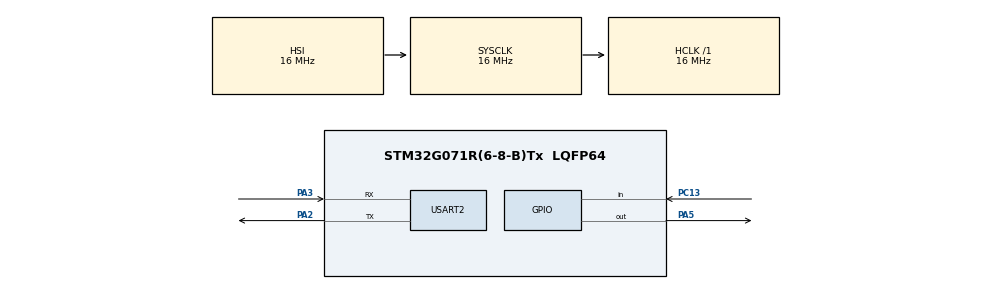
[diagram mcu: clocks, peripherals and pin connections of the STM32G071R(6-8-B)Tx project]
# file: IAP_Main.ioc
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CRC.CRCLength=CRC_POLYLENGTH_16B
CRC.DefaultInitValueUse=DEFAULT_INIT_VALUE_DISABLE
CRC.DefaultPolynomialUse=DEFAULT_POLYNOMIAL_DISABLE
Mcu.Family=STM32G0
Mcu.Name=STM32G071R(6-8-B)Tx
Mcu.Package=LQFP64
PA2.Mode=Asynchronous
PA2.Signal=USART2_TX
PA3.Mode=Asynchronous
PA3.Signal=USART2_RX
PA5.Signal=GPIO_Output
PC13.Signal=GPIO_Input
ProjectManager.HeapSize=0x200
ProjectManager.StackSize=0x400
ProjectManager.TargetToolchain=STM32CubeIDE
RCC.AHBFreq_Value=16000000
RCC.CortexFreq_Value=16000000
RCC.EXTERNAL_CLOCK_VALUE=12288000
RCC.HCLKFreq_Value=16000000
RCC.HSE_VALUE=8000000
RCC.HSI_VALUE=16000000
RCC.LSE_VALUE=32768
RCC.SYSCLKFreq_VALUE=16000000
RCC.VCOOutputFreq_Value=128000000
USART2.VirtualMode-Asynchronous=VM_ASYNC
VP_CRC_VS_CRC.Mode=CRC_Activate
board=NUCLEO-G071RB

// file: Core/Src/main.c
/* USER CODE BEGIN Header */
/**
  ******************************************************************************
  * @file           : main.c
  * @brief          : Main program body
  ******************************************************************************
  * @attention
  *
  * Copyright (c) 2023 STMicroelectronics.
  * All rights reserved.
  *
  * This software is licensed under terms that can be found in the LICENSE file
  * in the root directory of this software component.
  * If no LICENSE file comes with this software, it is provided AS-IS.
  *
  ******************************************************************************
  */
/* USER CODE END Header */
#include "main.h"

/* USER CODE BEGIN Includes */
#include "menu.h"
/* USER CODE END Includes */

CRC_HandleTypeDef hcrc;

UART_HandleTypeDef huart2;

/* USER CODE BEGIN PV */
extern pFunction JumpToApplication;
extern uint32_t JumpAddress;
/* USER CODE END PV */

void SystemClock_Config(void);
static void MX_GPIO_Init(void);
static void MX_USART2_UART_Init(void);
static void MX_CRC_Init(void);

int main(void)
{

  /* MCU Configuration--------------------------------------------------------*/

  /* Reset of all peripherals, Initializes the Flash interface and the Systick. */
  HAL_Init();

  /* Configure the system clock */
  SystemClock_Config();

  /* Initialize all configured peripherals */
  MX_GPIO_Init();
  MX_USART2_UART_Init();
  MX_CRC_Init();
  /* USER CODE BEGIN 2 */
  if (HAL_GPIO_ReadPin(BTN1_GPIO_Port,BTN1_Pin) == GPIO_PIN_SET)
  {
	  /* Initialise Flash */
	  FLASH_If_Init();
	  /* Display main menu */
	  Main_Menu ();
  }
  /* Keep the user application running */
  else
  {
	  /* Test if user code is programmed starting from address "APPLICATION_ADDRESS" */
	  if (((*(__IO uint32_t*)APPLICATION_ADDRESS) & 0x2FFE0000 ) == 0x20000000)
	  {
		  /* Jump to user application */
		  JumpAddress = *(__IO uint32_t*) (APPLICATION_ADDRESS + 4);
		  JumpToApplication = (pFunction) JumpAddress;
		  /* Initialize user application's Stack Pointer */
		  __set_MSP(*(__IO uint32_t*) APPLICATION_ADDRESS);
		  JumpToApplication();
	  }
  }
  /* USER CODE END 2 */

  /* Infinite loop */
  while (1)
  {

  }
}

void SystemClock_Config(void)
{
  RCC_OscInitTypeDef RCC_OscInitStruct = {0};
  RCC_ClkInitTypeDef RCC_ClkInitStruct = {0};

  /** Configure the main internal regulator output voltage
  */
  HAL_PWREx_ControlVoltageScaling(PWR_REGULATOR_VOLTAGE_SCALE1);

  /** Initializes the RCC Oscillators according to the specified parameters
  * in the RCC_OscInitTypeDef structure.
  */
  RCC_OscInitStruct.OscillatorType = RCC_OSCILLATORTYPE_HSI;
  RCC_OscInitStruct.HSIState = RCC_HSI_ON;
  RCC_OscInitStruct.HSIDiv = RCC_HSI_DIV1;
  RCC_OscInitStruct.HSICalibrationValue = RCC_HSICALIBRATION_DEFAULT;
  RCC_OscInitStruct.PLL.PLLState = RCC_PLL_NONE;
  if (HAL_RCC_OscConfig(&RCC_OscInitStruct) != HAL_OK)
  {
    Error_Handler();
  }

  /** Initializes the CPU, AHB and APB buses clocks
  */
  RCC_ClkInitStruct.ClockType = RCC_CLOCKTYPE_HCLK|RCC_CLOCKTYPE_SYSCLK
                              |RCC_CLOCKTYPE_PCLK1;
  RCC_ClkInitStruct.SYSCLKSource = RCC_SYSCLKSOURCE_HSI;
  RCC_ClkInitStruct.AHBCLKDivider = RCC_SYSCLK_DIV1;
  RCC_ClkInitStruct.APB1CLKDivider = RCC_HCLK_DIV1;

  if (HAL_RCC_ClockConfig(&RCC_ClkInitStruct, FLASH_LATENCY_0) != HAL_OK)
  {
    Error_Handler();
  }
}

static void MX_CRC_Init(void)
{

  hcrc.Instance = CRC;
  hcrc.Init.DefaultPolynomialUse = DEFAULT_POLYNOMIAL_DISABLE;
  hcrc.Init.DefaultInitValueUse = DEFAULT_INIT_VALUE_DISABLE;
  hcrc.Init.GeneratingPolynomial = 0x1021;  //CRC polynomial for ymodem
  hcrc.Init.CRCLength = CRC_POLYLENGTH_16B;
  hcrc.Init.InitValue = 0;
  hcrc.Init.InputDataInversionMode = CRC_INPUTDATA_INVERSION_NONE;
  hcrc.Init.OutputDataInversionMode = CRC_OUTPUTDATA_INVERSION_DISABLE;
  hcrc.InputDataFormat = CRC_INPUTDATA_FORMAT_BYTES;
  if (HAL_CRC_Init(&hcrc) != HAL_OK)
  {
    Error_Handler();
  }

}

static void MX_USART2_UART_Init(void)
{

  huart2.Instance = USART2;
  huart2.Init.BaudRate = 115200;
  huart2.Init.WordLength = UART_WORDLENGTH_8B;
  huart2.Init.StopBits = UART_STOPBITS_1;
  huart2.Init.Parity = UART_PARITY_NONE;
  huart2.Init.Mode = UART_MODE_TX_RX;
  huart2.Init.HwFlowCtl = UART_HWCONTROL_NONE;
  huart2.Init.OverSampling = UART_OVERSAMPLING_16;
  huart2.Init.OneBitSampling = UART_ONE_BIT_SAMPLE_DISABLE;
  huart2.Init.ClockPrescaler = UART_PRESCALER_DIV1;
  huart2.AdvancedInit.AdvFeatureInit = UART_ADVFEATURE_NO_INIT;
  if (HAL_UART_Init(&huart2) != HAL_OK)
  {
    Error_Handler();
  }
  if (HAL_UARTEx_SetTxFifoThreshold(&huart2, UART_TXFIFO_THRESHOLD_1_8) != HAL_OK)
  {
    Error_Handler();
  }
  if (HAL_UARTEx_SetRxFifoThreshold(&huart2, UART_RXFIFO_THRESHOLD_1_8) != HAL_OK)
  {
    Error_Handler();
  }
  if (HAL_UARTEx_DisableFifoMode(&huart2) != HAL_OK)
  {
    Error_Handler();
  }

}

static void MX_GPIO_Init(void)
{
  GPIO_InitTypeDef GPIO_InitStruct = {0};

  /* GPIO Ports Clock Enable */
  __HAL_RCC_GPIOC_CLK_ENABLE();
  __HAL_RCC_GPIOA_CLK_ENABLE();

  /*Configure GPIO pin Output Level */
  HAL_GPIO_WritePin(GPIOA, GPIO_PIN_5, GPIO_PIN_RESET);

  /*Configure GPIO pin : PC13 */
  GPIO_InitStruct.Pin = GPIO_PIN_13;
  GPIO_InitStruct.Mode = GPIO_MODE_INPUT;
  GPIO_InitStruct.Pull = GPIO_NOPULL;
  HAL_GPIO_Init(GPIOC, &GPIO_InitStruct);

  /*Configure GPIO pin : PA5 */
  GPIO_InitStruct.Pin = GPIO_PIN_5;
  GPIO_InitStruct.Mode = GPIO_MODE_OUTPUT_PP;
  GPIO_InitStruct.Pull = GPIO_NOPULL;
  GPIO_InitStruct.Speed = GPIO_SPEED_FREQ_LOW;
  HAL_GPIO_Init(GPIOA, &GPIO_InitStruct);

}

void Error_Handler(void)
{
  __disable_irq();
  while (1)
  {
  }
}
